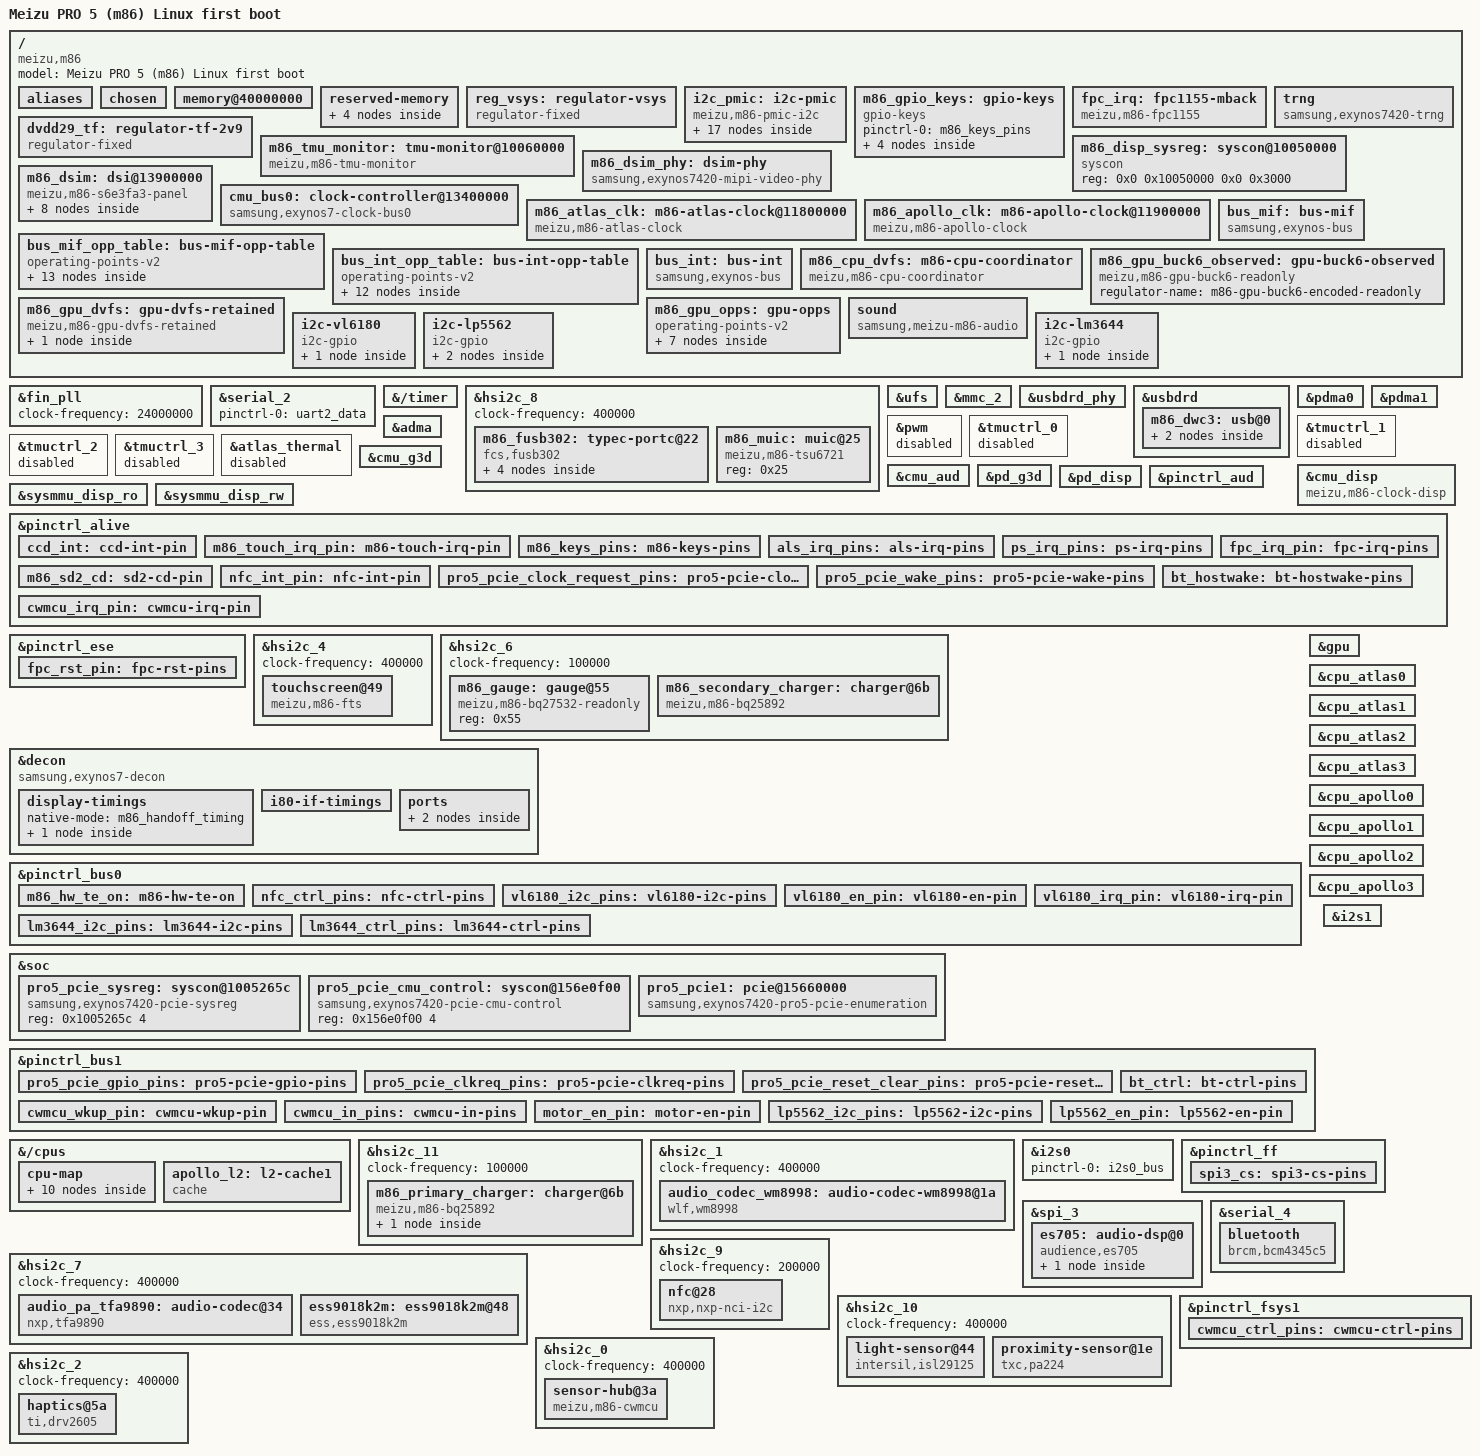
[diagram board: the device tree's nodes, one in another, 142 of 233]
// SPDX-License-Identifier: GPL-2.0-only
/*
 * Meizu PRO 5 (m86), conservative Linux 6.6 first-boot board description.
 * Board wiring: meizuosc/m576 ubuntu 5a0c442 and archived m86 raw DTB.
 * Requires the project's pinned Exynos7420 SoC patch (A53 + MCT nodes).
 */
/dts-v1/;

#include "exynos7.dtsi"
#include <dt-bindings/gpio/gpio.h>
#include <dt-bindings/input/ti-drv260x.h>
#include <dt-bindings/leds/common.h>
#include <dt-bindings/usb/pd.h>

/ {
	model = "Meizu PRO 5 (m86) Linux first boot";
	compatible = "meizu,m86", "samsung,exynos7420", "samsung,exynos7";

	aliases {
		serial0 = &serial_2;
		serial4 = &serial_4;
		i2c2 = &hsi2c_2;
		i2c6 = &hsi2c_6;
		i2c8 = &hsi2c_8;
		i2c10 = &hsi2c_10;
		i2c11 = &hsi2c_11;
		i2c5 = &i2c_pmic;
	};

	chosen {
		stdout-path = "serial0:115200n8";
		bootargs = "earlycon=exynos4210,0x14c30000 console=ttySAC0,115200n8 rdinit=/init maxcpus=8 clk_ignore_unused pd_ignore_unused loglevel=4 nokaslr no_console_suspend panic=5 oops=panic";
	};

	/*
	 * Built-in FDT: 3 GiB base map + placeholder for 4 GiB high bank
	 * [0x1_0000_0000, 0x1_4000_0000), populated at boot from firmware FDT.
	 */
	memory@40000000 {
		device_type = "memory";
		reg = <0x0 0x40000000 0x0 0xc0000000>,
		      <0x1 0x00000000 0x0 0x00000000>;
	};

	reserved-memory {
		#address-cells = <2>;
		#size-cells = <2>;
		ranges;

		/*
		 * Preserves only the bootloader display handoff buffer (through 0xe4800000).
		 * Reclaimed: vendor-log (32 MiB) and legacy modem/media/video (335.5 MiB).
		 */
		vendor-reserved@e1000000 {
			reg = <0x0 0xe1000000 0x0 0x03800000>;
			no-map;
		};

		/* Observed on 860BCMT226FG; matches the original Recovery SECLOG. */
		seclog@f9780000 {
			reg = <0x0 0xf9780000 0x0 0x00080000>;
			no-map;
		};

		vendor-reserved@f9800000 {
			reg = <0x0 0xf9800000 0x0 0x06800000>;
			no-map;
		};

		decon_iova_resv: decon-iova-reserved {
			iommu-addresses = <&decon 0xe0000000 0x04200000>;
		};
	};

	reg_vsys: regulator-vsys {
		compatible = "regulator-fixed";
		regulator-name = "vsys";
		regulator-min-microvolt = <3800000>;
		regulator-max-microvolt = <3800000>;
		regulator-always-on;
	};

	/*
	 * RTC-only PMIC path. The adapter checks/holds non-running APM in
	 * reset before requesting GPIOs. No default pinctrl state may run
	 * ahead of that guard. The regulator driver remains disabled.
	 */
	i2c_pmic: i2c-pmic {
		compatible = "meizu,m86-pmic-i2c", "i2c-gpio";
		meizu,pmu = <&pmu_system_controller>;
		#address-cells = <1>;
		#size-cells = <0>;
		sda-gpios = <&gpg3 2 (GPIO_ACTIVE_HIGH | GPIO_OPEN_DRAIN)>;
		scl-gpios = <&gpg3 3 (GPIO_ACTIVE_HIGH | GPIO_OPEN_DRAIN)>;
		i2c-gpio,delay-us = <5>;
		i2c-gpio,timeout-ms = <100>;
		status = "okay";

		pmic@66 {
			compatible = "samsung,s2mps15-pmic";
			reg = <0x66>;
			/* No PMIC IRQ: RTC read/write only, no alarm or wakeup. */
			regulators {
				/* Dynamic MIF, CPU, and INT rails: BUCK1, BUCK2, BUCK3, BUCK4 */
				m86_buck1_mif: BUCK1 {
					regulator-name = "vdd_mif";
					regulator-min-microvolt = <500000>;
					regulator-max-microvolt = <1100000>;
					regulator-always-on;
				};
				m86_buck2_cpu: BUCK2 {
					regulator-name = "vdd_atlas";
					regulator-min-microvolt = <500000>;
					regulator-max-microvolt = <1300000>;
					regulator-always-on;
					meizu,cpu-dvfs-active;
				};
				m86_buck3_cpu: BUCK3 {
					regulator-name = "vdd_apollo";
					regulator-min-microvolt = <500000>;
					regulator-max-microvolt = <1200000>;
					regulator-always-on;
					meizu,cpu-dvfs-active;
				};
				m86_buck4_int: BUCK4 {
					regulator-name = "vdd_int";
					regulator-min-microvolt = <500000>;
					regulator-max-microvolt = <1000000>;
					regulator-always-on;
				};
			};
		};
	};
};

&fin_pll {
	clock-frequency = <24000000>;
};

&serial_2 {
	pinctrl-names = "default";
	pinctrl-0 = <&uart2_data>;
	status = "okay";
};

/*
 * Preserve all MPIDRs, allowing the boot CPU to be identified whichever
 * cluster U-Boot entered. Bring up both clusters before capability finalization.
 * Stock PSCI 0.1 uses exactly the inherited CPU_ON/OFF function IDs.
 */
&{/timer} {
	clock-frequency = <24000000>;
	interrupt-names = "sec-phys", "phys", "hyp-phys";
	interrupts = <GIC_PPI 13 (GIC_CPU_MASK_SIMPLE(8) | IRQ_TYPE_LEVEL_LOW)>,
		     <GIC_PPI 14 (GIC_CPU_MASK_SIMPLE(8) | IRQ_TYPE_LEVEL_LOW)>,
		     <GIC_PPI 10 (GIC_CPU_MASK_SIMPLE(8) | IRQ_TYPE_LEVEL_LOW)>;
};

&hsi2c_8 {
	status = "okay";
	clock-frequency = <400000>;

	m86_fusb302: typec-portc@22 {
		compatible = "fcs,fusb302";
		reg = <0x22>;
		interrupt-parent = <&gpa1>;
		interrupts = <5 IRQ_TYPE_LEVEL_LOW>;
		pd-on-gpios = <&gpr3 4 GPIO_ACTIVE_HIGH>;
		pinctrl-names = "default";
		pinctrl-0 = <&ccd_int>;
		vbus-supply = <&usb_otg_vbus>;

		connector {
			compatible = "usb-c-connector";
			label = "USB-C";
			power-role = "dual";
			data-role = "dual";
			try-power-role = "sink";
			source-pdos = <PDO_FIXED(5000, 1500, PDO_FIXED_USB_COMM)>;
			sink-pdos = <
				PDO_FIXED(5000, 3000, PDO_FIXED_USB_COMM)
				PDO_FIXED(9000, 3000, PDO_FIXED_USB_COMM)
				PDO_FIXED(12000, 2000, PDO_FIXED_USB_COMM)
			>;
			op-sink-microwatt = <24000000>;
			usb-role-switch = <&m86_dwc3>;

			ports {
				#address-cells = <1>;
				#size-cells = <0>;

				port@0 {
					reg = <0>;
					usbc_hs: endpoint {
						remote-endpoint = <&dwc3_ep>;
					};
				};
			};
		};
	};
	m86_muic: muic@25 {
		compatible = "meizu,m86-tsu6721";
		reg = <0x25>;
	};
};

&ufs {
	samsung,bus = <&bus_mif>;
	interconnects = <&bus_int &bus_mif>;
	interconnect-names = "dma-mem";
	status = "okay";
};

&mmc_2 {
	status = "okay";
	num-slots = <1>;
	cap-sd-highspeed;
	sd-uhs-sdr12;
	sd-uhs-sdr25;
	sd-uhs-sdr50;
	sd-uhs-sdr104;
	sd-uhs-ddr50;
	card-detect-delay = <200>;
	samsung,dw-mshc-ciu-div = <3>;
	samsung,dw-mshc-sdr-timing = <3 0 3 2>;
	samsung,dw-mshc-ddr-timing = <3 0 2 1>;
	fifo-depth = <0x40>;
	bus-width = <4>;
	cd-gpios = <&gpa1 3 GPIO_ACTIVE_LOW>;
	vmmc-supply = <&dvdd29_tf>;
	vqmmc-supply = <&ldo2_reg>;
	pinctrl-names = "default";
	pinctrl-0 = <&sd2_clk &sd2_cmd &sd2_bus1 &sd2_bus4 &m86_sd2_cd>;
};

&usbdrd_phy {
	status = "okay";
};

&usbdrd {
	status = "okay";

	m86_dwc3: usb@0 {
		dr_mode = "otg";
		usb-role-switch;
		role-switch-default-mode = "peripheral";
		maximum-speed = "high-speed";
		snps,dis_u2_susphy_quirk;
		snps,dis_enblslpm_quirk;

		port {
			dwc3_ep: endpoint {
				remote-endpoint = <&usbc_hs>;
			};
		};
	};
};

/* Avoid unneeded first-boot accesses and the S6 display/audio sequences. */
&pdma0 { status = "okay"; };
&pdma1 { status = "okay"; };
&adma { status = "okay"; };
&pwm { status = "disabled"; };
&tmuctrl_0 { status = "disabled"; };
&tmuctrl_1 { status = "disabled"; };
&tmuctrl_2 { status = "disabled"; };
&tmuctrl_3 { status = "disabled"; };
&atlas_thermal { status = "disabled"; };
&cmu_g3d { status = "okay"; };
&cmu_aud { status = "okay"; };
&cmu_disp { status = "disabled"; };
&pd_g3d { status = "okay"; };
&pd_disp { status = "disabled"; };
&pinctrl_aud { status = "okay"; };
&sysmmu_disp_ro { status = "disabled"; };
&sysmmu_disp_rw { status = "disabled"; };

// SPDX-License-Identifier: GPL-2.0-only
/* Include after the board DTS root and pinctrl definitions.
 * PMIC supplies are retained from the bootloader, not registered/reconfigured.
 */
#include <dt-bindings/gpio/gpio.h>
#include <dt-bindings/input/input.h>
#include <dt-bindings/interrupt-controller/irq.h>

/ {
	m86_gpio_keys: gpio-keys {
		compatible = "gpio-keys";
		pinctrl-names = "default";
		pinctrl-0 = <&m86_keys_pins>;

		power {
			label = "Power";
			linux,code = <KEY_POWER>;
			gpios = <&gpa2 4 GPIO_ACTIVE_LOW>;
			debounce-interval = <25>;
			wakeup-source;
		};
		volume-down {
			label = "Volume down";
			linux,code = <KEY_VOLUMEDOWN>;
			gpios = <&gpa1 2 GPIO_ACTIVE_LOW>;
			debounce-interval = <10>;
		};
		volume-up {
			label = "Volume up";
			linux,code = <KEY_VOLUMEUP>;
			gpios = <&gpa0 7 GPIO_ACTIVE_LOW>;
			debounce-interval = <10>;
		};
		home {
			label = "Home";
			linux,code = <KEY_LEFTMETA>;
			gpios = <&gpa3 2 GPIO_ACTIVE_LOW>;
			debounce-interval = <10>;
			wakeup-source;
		};
	};

	fpc_irq: fpc1155-mback {
		compatible = "meizu,m86-fpc1155", "fpc,fpc_irq";
		irq-gpios = <&gpa2 2 GPIO_ACTIVE_HIGH>;
		reset-gpios = <&gpv7 4 GPIO_ACTIVE_HIGH>;
		vdd-supply = <&ldo14_reg>;
		clocks = <&clock_peric1 PCLK_SPI4>, <&clock_peric1 SCLK_SPI4>;
		clock-names = "pclk", "sclk";
		pinctrl-names = "default";
		pinctrl-0 = <&fpc_irq_pin &fpc_rst_pin>;
		wakeup-source;
	};

	dvdd29_tf: regulator-tf-2v9 {
		compatible = "regulator-fixed";
		regulator-name = "vmmc_sdcard";
		regulator-min-microvolt = <2900000>;
		regulator-max-microvolt = <2900000>;
		gpio = <&gpf2 2 GPIO_ACTIVE_HIGH>;
		enable-active-high;
	};

	trng {
		compatible = "samsung,exynos7420-trng", "samsung,exynos850-trng";
	};
};

&pinctrl_alive {
	ccd_int: ccd-int-pin {
		samsung,pins = "gpa1-5";
		samsung,pin-function = <0xf>;
		samsung,pin-pud = <0>;
	};
	m86_touch_irq_pin: m86-touch-irq-pin {
		samsung,pins = "gpa1-1";
		samsung,pin-function = <0xf>;
		samsung,pin-pud = <3>;
	};
	m86_keys_pins: m86-keys-pins {
		samsung,pins = "gpa2-4", "gpa1-2", "gpa0-7", "gpa3-2";
		samsung,pin-function = <0xf>;
		samsung,pin-pud = <0>;
	};
	als_irq_pins: als-irq-pins {
		samsung,pins = "gpa2-5";
		samsung,pin-function = <0xf>;
		samsung,pin-pud = <3>;
		samsung,pin-drv = <0>;
	};
	ps_irq_pins: ps-irq-pins {
		samsung,pins = "gpa3-4";
		samsung,pin-function = <0xf>;
		samsung,pin-pud = <3>;
		samsung,pin-drv = <0>;
	};
	fpc_irq_pin: fpc-irq-pins {
		samsung,pins = "gpa2-2";
		samsung,pin-function = <0xf>;
		samsung,pin-pud = <0>;
	};
	m86_sd2_cd: sd2-cd-pin {
		samsung,pins = "gpa1-3";
		samsung,pin-function = <0xf>;
		samsung,pin-pud = <3>;
	};
	nfc_int_pin: nfc-int-pin {
		samsung,pins = "gpa2-1";
		samsung,pin-function = <0xf>;
		samsung,pin-pud = <1>;
	};
};

&pinctrl_ese {
	fpc_rst_pin: fpc-rst-pins {
		samsung,pins = "gpv7-4";
		samsung,pin-function = <1>;
		samsung,pin-pud = <0>;
	};
};

&hsi2c_4 {
	status = "okay";
	clock-frequency = <400000>;
	touchscreen@49 {
		compatible = "meizu,m86-fts";
		reg = <0x49>;
		pinctrl-names = "default";
		pinctrl-0 = <&m86_touch_irq_pin>;
		interrupt-parent = <&gpa1>;
		interrupts = <1 IRQ_TYPE_LEVEL_LOW>;
		touchscreen-size-x = <1080>;
		touchscreen-size-y = <1920>;
	};
};

/* Integration proposal, not included by the active board DTS.
 * Keep the inherited Exynos7 TMU disabled; this monitor owns all four windows.
 * Driver enables clocks and sensing; no threshold or trim writes.
 * A 95 C software critical zone polls maximum of all four P0 sensors.
 */
/ {
	m86_tmu_monitor: tmu-monitor@10060000 {
		compatible = "meizu,m86-tmu-monitor";
		reg = <0 0x10060000 0 0x200>, <0 0x10064000 0 0x200>,
		      <0 0x10068000 0 0x200>, <0 0x1006c000 0 0x200>;
		interrupts = <GIC_SPI 108 IRQ_TYPE_LEVEL_HIGH>,
		             <GIC_SPI 124 IRQ_TYPE_LEVEL_HIGH>,
		             <GIC_SPI 109 IRQ_TYPE_LEVEL_HIGH>,
		             <GIC_SPI 107 IRQ_TYPE_LEVEL_HIGH>;
		clocks = <&clock_peris PCLK_TMU>, <&clock_peris SCLK_TMU>;
		clock-names = "tmu_apbif", "tmu_sclk";
	};
};

&hsi2c_6 {
	status = "okay";
	clock-frequency = <100000>;

	m86_gauge: gauge@55 {
		compatible = "meizu,m86-bq27532-readonly";
		reg = <0x55>;
	};
	m86_secondary_charger: charger@6b {
		compatible = "meizu,m86-bq25892", "ti,bq25892", "ti,bq25890";
		reg = <0x6b>;
		interrupt-parent = <&gpa0>;
		interrupts = <2 IRQ_TYPE_EDGE_FALLING>;
		enable-gpios = <&gpr3 2 GPIO_ACTIVE_LOW>;
		linux,skip-reset;
		ti,charge-current = <2250000>;
		ti,battery-regulation-voltage = <4352000>;
		ti,termination-current = <64000>;
		ti,precharge-current = <128000>;
		ti,minimum-sys-voltage = <3500000>;
		ti,boost-voltage = <5000000>;
		ti,boost-max-current = <500000>;
		ti,thermal-regulation-threshold = <80>;
		meizu,secondary-charger;
	};
};

&tmuctrl_0 { status = "disabled"; };
&tmuctrl_1 { status = "disabled"; };
&tmuctrl_2 { status = "disabled"; };
&tmuctrl_3 { status = "disabled"; };

/* Replace the empty regulators child on the board's existing S2MPS15 node.
 * These voltage constraints can write voltage at probe if firmware differs.
 * First read raw L18/19/21/23CTRL and record observed voltage/enable; don't
 * activate this proposal without evaluating the actual state.
 * Existing full constraints apply only to these registered rails on M86.
 */
&i2c_pmic {
  pmic@66 {
	regulators {
		m86_wm8998_1v8: LDO16 {
			regulator-name = "vdd18_audio";
			regulator-min-microvolt = <1800000>;
			regulator-max-microvolt = <1800000>;
			regulator-boot-on;
			regulator-always-on;
		};
		ldo17_reg: LDO17 {
			regulator-name = "vdd28_sen";
			regulator-min-microvolt = <2800000>;
			regulator-max-microvolt = <2800000>;
			regulator-boot-on;
			regulator-always-on;
		};
		m86_lcd_1v8: LDO18 {
			regulator-name = "vdd18_lcd";
			regulator-min-microvolt = <1800000>;
			regulator-max-microvolt = <1800000>;
			regulator-boot-on;
			regulator-always-on;
		};
		m86_lcd_3v3: LDO19 {
			regulator-name = "vdd33_lcd";
			regulator-min-microvolt = <3300000>;
			regulator-max-microvolt = <3300000>;
			regulator-boot-on;
			regulator-always-on;
		};
		m86_touch_3v3: LDO21 {
			regulator-name = "vdd33_touch";
			regulator-min-microvolt = <2900000>;
			regulator-max-microvolt = <2900000>;
			regulator-boot-on;
			regulator-always-on;
		};
		m86_es705_1v1: LDO22 {
			regulator-name = "vdd11_nr";
			regulator-min-microvolt = <1100000>;
			regulator-max-microvolt = <1100000>;
		};
		m86_touch_1v8: LDO23 {
			regulator-name = "vdd18_touch";
			regulator-min-microvolt = <1800000>;
			regulator-max-microvolt = <1800000>;
			regulator-boot-on;
			regulator-always-on;
		};
		ldo25_reg: LDO25 {
			regulator-name = "vdd28_ps";
			regulator-min-microvolt = <2800000>;
			regulator-max-microvolt = <2800000>;
			regulator-boot-on;
		};
		ldo14_reg: LDO14 {
			regulator-name = "vdd28_fp";
			regulator-min-microvolt = <1800000>;
			regulator-max-microvolt = <1800000>;
			regulator-boot-on;
			regulator-always-on;
		};
		ldo2_reg: LDO2 {
			regulator-name = "vqmmc_sdcard";
			regulator-min-microvolt = <1800000>;
			regulator-max-microvolt = <3300000>;
			regulator-boot-on;
		};
		ldo27_reg: LDO27 {
			regulator-name = "vdd18_nfc";
			regulator-min-microvolt = <1800000>;
			regulator-max-microvolt = <1800000>;
			regulator-boot-on;
			regulator-always-on;
		};
	};
  };
};

/* Command-mode display handoff from the bootloader. */
&cmu_disp { status = "okay"; };
&pd_disp { status = "okay"; };
&sysmmu_disp_ro { status = "okay"; };
&sysmmu_disp_rw { status = "okay"; };
&decon {
	compatible = "samsung,exynos7-decon";
	clocks = <&cmu_disp CLK_PCLK_DECON0>, <&cmu_disp CLK_ACLK_DECON0>,
	         <&cmu_disp CLK_SCLK_DECON0_ECLK>, <&cmu_disp CLK_SCLK_DECON0_VCLK>;
	clock-names = "pclk_decon0", "aclk_decon0", "decon0_eclk", "decon0_vclk";
	te-gpios = <&gpc0 1 GPIO_ACTIVE_HIGH>;
	samsung,bus = <&bus_mif>;
	interconnects = <&bus_int &bus_mif>;
	interconnect-names = "dma-mem";
	memory-region = <&decon_iova_resv>;
	status = "okay";
 display-timings {
  native-mode = <&m86_handoff_timing>;
  m86_handoff_timing: timing {
   clock-frequency = <125216000>;
   hactive = <1080>; vactive = <1920>;
   hfront-porch = <1>; hback-porch = <1>; hsync-len = <1>;
   vfront-porch = <5>; vback-porch = <1>; vsync-len = <1>;
  };
 };
 i80-if-timings { };
 ports {
  #address-cells = <1>;
  #size-cells = <0>;
  port@0 {
   reg = <0>;
   m86_decon_out: endpoint { remote-endpoint = <&m86_dsim_in>; };
  };
 };
};
// SPDX-License-Identifier: GPL-2.0-only
/* DSIM/PHY portion only. Parent adds DECON graph, panel/reset/TE and supplies. */
#include <dt-bindings/clock/exynos7-clk.h>
#include <dt-bindings/interrupt-controller/arm-gic.h>

/ {
	m86_disp_sysreg: syscon@10050000 {
		compatible = "syscon";
		reg = <0x0 0x10050000 0x0 0x3000>;
	};
	m86_dsim_phy: dsim-phy {
		compatible = "samsung,exynos7420-mipi-video-phy";
		samsung,pmu-syscon = <&pmu_system_controller>;
		samsung,disp-sysreg = <&m86_disp_sysreg>;
		#phy-cells = <1>;
	};
	m86_dsim: dsi@13900000 {
		/* Official HW TE input is separate from the gpc0-1 TE EINT. */
		pinctrl-names = "default";
		pinctrl-0 = <&m86_hw_te_on>;
		compatible = "samsung,exynos7420-mipi-dsi";
		reg = <0x0 0x13900000 0x0 0x1000>;
		interrupt-parent = <&gic>;
		interrupts = <GIC_SPI 196 IRQ_TYPE_LEVEL_HIGH>;
		clocks = <&cmu_disp CLK_PCLK_DSIM0>, <&fin_pll>,
			<&cmu_disp CLK_PHYCLK_MIPIDPHY0_BITCLKDIV8>,
			<&cmu_disp CLK_PHYCLK_MIPIDPHY0_RXCLKESC0>,
			<&cmu_disp CLK_SCLK_RGB_VCLK_TO_DSIM0>;
		clock-names = "bus_clk", "sclk_mipi",
			"phyclk_mipidphy0_bitclkdiv8",
			"phyclk_mipidphy0_rxclkesc0", "sclk_rgb_vclk_to_dsim0";
		assigned-clocks = <&cmu_disp CLK_MOUT_MIPIDPHY0_BIT>,
			<&cmu_disp CLK_MOUT_MIPIDPHY0_RX>;
		assigned-clock-parents = <&cmu_disp CLK_FOUT_MIPIDPHY0_BIT>,
			<&cmu_disp CLK_FOUT_MIPIDPHY0_RX>;
		phys = <&m86_dsim_phy 0>;
		phy-names = "dsim";
		samsung,pll-clock-frequency = <24000000>;
		samsung,burst-clock-frequency = <650000000>;
		samsung,esc-clock-frequency = <20000000>;
		samsung,mic-enabled;
		status = "disabled";
		/* Required: add vddcore/vddio supply phandles and ports/panel. */
	};
};
&m86_dsim {
 #address-cells = <1>;
 #size-cells = <0>;
 ports {
  #address-cells = <1>;
  #size-cells = <0>;
  port@0 {
   reg = <0>;
   m86_dsim_in: endpoint { remote-endpoint = <&m86_decon_out>; };
  };
  port@1 {
   reg = <1>;
   m86_dsim_out: endpoint { remote-endpoint = <&m86_panel_in>; data-lanes = <0 1>; };
  };
 };
 panel@0 {
  compatible = "meizu,m86-s6e3fa3";
  te-gpios = <&gpc0 1 GPIO_ACTIVE_HIGH>;
  reg = <0>;
  vci-supply = <&m86_lcd_3v3>;
  vdd3-supply = <&m86_lcd_1v8>;
  reset-gpios = <&gpc3 3 GPIO_ACTIVE_LOW>;
  port { m86_panel_in: endpoint { remote-endpoint = <&m86_dsim_out>; }; };
 };
};

/* Preserve the bootloader display clocks for the zenlte handoff path. */
&cmu_disp {
 /* Decode the inherited PLL correctly without retuning the live display. */
 compatible = "meizu,m86-clock-disp";
};

/ {
 cmu_bus0: clock-controller@13400000 {
  compatible = "samsung,exynos7-clock-bus0";
  reg = <0x0 0x13400000 0x0 0x1000>;
  #clock-cells = <1>;
  clocks = <&fin_pll>, <&clock_topc CLK_ACLK_BUS0_532>;
  clock-names = "fin_pll", "top_aclk_bus0_532";
 };
};

/* Handoff keeps the inherited TOP0 ECLK parent and divider. */


/* Official disp_teson: GPG0-1 function2 routes the external hardware TE. */
&pinctrl_bus0 {
 m86_hw_te_on: m86-hw-te-on {
  samsung,pins = "gpg0-1";
  samsung,pin-function = <2>;
 };
 nfc_ctrl_pins: nfc-ctrl-pins {
  samsung,pins = "gpc3-0", "gpc3-4", "gpc3-7";
  samsung,pin-function = <1>;
  samsung,pin-pud = <0>;
  samsung,pin-con-pdn = <3>;
 };
};

/* S6E3FA3 command-mode panel and backlight controller */
&m86_dsim {
	compatible = "meizu,m86-s6e3fa3-panel", "meizu,m86-dsim-handoff-backlight";
	/delete-property/ pinctrl-names;
	/delete-property/ pinctrl-0;
	/delete-property/ assigned-clocks;
	/delete-property/ assigned-clock-parents;
	default-brightness = <68>;
	status = "okay";
};

/* Experimental retained-power GPU bring-up only.
 * Require observed G3D domain/BUCK6 on before booting this candidate.
 * No regulator voltage/control claims: missing mali-supply uses dummy supply.
 * Preserve external domain power rather than introducing unverified m86 PM.
 */
&gpu {
	/delete-property/ power-domains;
	status = "okay";
};

/* CPU regulator consumer links only; no OPP or cpufreq enablement. */
&cpu_atlas0 { cpu-supply = <&m86_buck2_cpu>; };
&cpu_atlas1 { cpu-supply = <&m86_buck2_cpu>; };
&cpu_atlas2 { cpu-supply = <&m86_buck2_cpu>; };
&cpu_atlas3 { cpu-supply = <&m86_buck2_cpu>; };
&cpu_apollo0 { cpu-supply = <&m86_buck3_cpu>; };
&cpu_apollo1 { cpu-supply = <&m86_buck3_cpu>; };
&cpu_apollo2 { cpu-supply = <&m86_buck3_cpu>; };
&cpu_apollo3 { cpu-supply = <&m86_buck3_cpu>; };

/* SPDX-License-Identifier: GPL-2.0-only */
/* Include after exynos7420-m86.dts; candidate clock/header patch required. */
#include <dt-bindings/clock/exynos7-clk.h>
#include <dt-bindings/gpio/gpio.h>
#include <dt-bindings/interrupt-controller/arm-gic.h>

&soc {
	/* Preserve SoC MMIO and translate the channel-1 PCIe outbound aperture. */
	ranges = <0x00000000 0x0 0x00000000 0x18000000>,
	         <0x1c000000 0x0 0x1c000000 0x04000000>;
	/* Narrow SYSREG field, no existing syscon covers this register. */
	pro5_pcie_sysreg: syscon@1005265c {
		compatible = "samsung,exynos7420-pcie-sysreg", "syscon";
		reg = <0x1005265c 4>;
	};
	/* This word lies outside clock_fsys1's existing 0xd00 range. */
	pro5_pcie_cmu_control: syscon@156e0f00 {
		compatible = "samsung,exynos7420-pcie-cmu-control", "syscon";
		reg = <0x156e0f00 4>;
	};
	pro5_pcie1: pcie@15660000 {
		compatible = "samsung,exynos7420-pro5-pcie-enumeration";
		reg = <0x15660000 0x1000>, <0x15630000 0x1000>,
		      <0x156f00e4 4>, <0x157b0000 0x1000>,
		      <0x1c000000 0x1000>;
		reg-names = "elbi", "phy", "pcs", "dbi", "config";
		samsung,pcie-sysreg = <&pro5_pcie_sysreg>;
		samsung,pmu-syscon = <&pmu_system_controller>;
		samsung,pcie-cmu-control = <&pro5_pcie_cmu_control>;
		device_type = "pci";
		#address-cells = <3>;
		#size-cells = <2>;
		bus-range = <0 255>;
		/* Inbound identity DMA aperture for the installed 3GB DRAM. */
		dma-ranges = <0x02000000 0 0x40000000 0x40000000 0 0xc0000000>;
		ranges = <0x82000000 0 0x1c011000 0x1c011000 0 0x03feefff>;
		num-lanes = <1>;
		max-link-speed = <1>;
		interrupts = <GIC_SPI 205 IRQ_TYPE_LEVEL_HIGH>;
		interrupt-names = "elbi";
		/* Interrupts are masked by the enumeration-only driver. */
		reset-gpios = <&gpg2 0 GPIO_ACTIVE_LOW>;
		reg-on-gpios = <&gpf5 6 GPIO_ACTIVE_HIGH>;
		pinctrl-names = "default";
		pinctrl-0 = <&pro5_pcie_gpio_pins &pro5_pcie_clkreq_pins
		             &pro5_pcie_reset_clear_pins &pro5_pcie_wake_pins
		             &pro5_pcie_clock_request_pins>;
		clocks = <&clock_fsys1 ACLK_XIU_WIFI1X>,
		         <&clock_fsys1 ACLK_AHB2AXI_PCIE_WIFI1>,
		         <&clock_fsys1 ACLK_PCIE_WIFI1_MSTR>,
		         <&clock_fsys1 ACLK_PCIE_WIFI1_SLV>,
		         <&clock_fsys1 ACLK_PCIE_WIFI1_DBI>,
		         <&clock_fsys1 ACLK_COMBO_PHY_PCS_WIFI1>,
		         <&clock_fsys1 PCLK_ASYNC_COMBO_PHY_WIFI1>,
		         <&clock_fsys1 SCLK_PCIE_LINK_WIFI1>,
		         <&clock_fsys1 SCLK_COMBO_PHY_WIFI1_26M>,
		         <&clock_fsys1 SCLK_PHY_FSYS1_USER>,
		         <&clock_fsys1 PHYCLK_PCIE_WIFI1_TX0_USER>,
		         <&clock_fsys1 PHYCLK_PCIE_WIFI1_RX0_USER>,
		         <&clock_fsys1 MOUT_FSYS1_PHYCLK_SEL0>,
		         <&clock_fsys1 MOUT_PHYCLK_PCIE_WIFI1_TX0_USER>,
		         <&clock_fsys1 MOUT_PHYCLK_PCIE_WIFI1_RX0_USER>,
		         <&clock_fsys1 MOUT_SCLK_PHY_FSYS1_USER>,
		         <&fin_pll>, <&clock_fsys1 PHYCLK_PCIE_WIFI1_TX0>,
		         <&clock_fsys1 PHYCLK_PCIE_WIFI1_RX0>,
		         <&clock_top1 CLK_SCLK_PHY_FSYS1>;
		clock-names = "aclk_xiu_wifi1x", "aclk_ahb2axi_pcie_wifi1",
		              "aclk_pcie_wifi1_mstr_aclk", "aclk_pcie_wifi1_slv_aclk",
		              "aclk_pcie_wifi1_dbi_aclk", "aclk_combo_phy_pcs_pclk_wifi1",
		              "pclk_async_combo_phy_wifi1", "sclk_pcie_link_wifi1_gated",
		              "sclk_combo_phy_wifi1_26m_gated", "sclk_phy_fsys1_gated",
		              "phyclk_pcie_wifi1_tx0_gated", "phyclk_pcie_wifi1_rx0_gated",
		              "combo-ref-mux", "phy-tx-mux", "phy-rx-mux", "phy-user-mux",
		              "combo-ref-parent", "phy-tx-parent", "phy-rx-parent", "phy-user-parent";
		/* The module selects these four parents explicitly after stage0.
		 * No assigned-clock writes occur before manual driver logging.
		 */
		status = "okay";
	};
};

&pinctrl_bus1 {
	pro5_pcie_gpio_pins: pro5-pcie-gpio-pins {
		samsung,pins = "gpf5-6", "gpg2-0";
		samsung,pin-function = <1>;
		samsung,pin-drv = <3>;
	};
	pro5_pcie_clkreq_pins: pro5-pcie-clkreq-pins {
		samsung,pins = "gpf0-6";
		samsung,pin-function = <2>;
		samsung,pin-pud = <0>;
		samsung,pin-drv = <3>;
	};
	pro5_pcie_reset_clear_pins: pro5-pcie-reset-clear-pins {
		samsung,pins = "gpg2-2";
		samsung,pin-function = <2>;
		samsung,pin-pud = <3>;
	};
};

&pinctrl_alive {
	pro5_pcie_clock_request_pins: pro5-pcie-clock-request-pins {
		samsung,pins = "gpa3-5";
		samsung,pin-function = <0xf>;
		samsung,pin-pud = <0>;
	};
	pro5_pcie_wake_pins: pro5-pcie-wake-pins {
		samsung,pins = "gpa3-3";
		samsung,pin-function = <0>;
		samsung,pin-pud = <0>;
	};
};

/* Include only with m86-topc-cpu-safe-mux.patch and reviewed driver. */
/ {
	m86_atlas_clk: m86-atlas-clock@11800000 {
		compatible = "meizu,m86-atlas-clock";
		reg = <0 0x11800000 0 0x1000>;
		#clock-cells = <0>;
		clocks = <&clock_topc CLK_MOUT_BUS0_ATLAS>, <&fin_pll>;
		clock-names = "safe", "fin";
		meizu,max-validated-frequency = <2100000000>;
	};
	m86_apollo_clk: m86-apollo-clock@11900000 {
		compatible = "meizu,m86-apollo-clock";
		reg = <0 0x11900000 0 0x1000>;
		#clock-cells = <0>;
		clocks = <&clock_topc CLK_MOUT_BUS0_APOLLO>, <&fin_pll>;
		clock-names = "safe", "fin";
		meizu,max-validated-frequency = <1500000000>;
	};
};
&cpu_atlas0 { clocks = <&m86_atlas_clk>; };
&cpu_atlas1 { clocks = <&m86_atlas_clk>; };
&cpu_atlas2 { clocks = <&m86_atlas_clk>; };
&cpu_atlas3 { clocks = <&m86_atlas_clk>; };
&cpu_apollo0 { clocks = <&m86_apollo_clk>; };
&cpu_apollo1 { clocks = <&m86_apollo_clk>; };
&cpu_apollo2 { clocks = <&m86_apollo_clk>; };
&cpu_apollo3 { clocks = <&m86_apollo_clk>; };

/* Review proposal only. Calibration flags require source-backed unit evidence;
 * bus-floor property must NOT be added until actual fixed MIF/INT mapping verified.
 * Add label m86_tmu_monitor to existing sensor node separately before inclusion.
 */
/ {
	bus_mif_opp_table: bus-mif-opp-table {
		compatible = "operating-points-v2";

		opp-100000000 {
			opp-hz = /bits/ 64 <100000000>;
			opp-microvolt = <600000>;
			required-opps = <&int_opp_100>;
		};
		opp-133000000 {
			opp-hz = /bits/ 64 <133000000>;
			opp-microvolt = <600000>;
			required-opps = <&int_opp_200>;
		};
		opp-167000000 {
			opp-hz = /bits/ 64 <167000000>;
			opp-microvolt = <600000>;
			required-opps = <&int_opp_200>;
		};
		opp-276000000 {
			opp-hz = /bits/ 64 <276000000>;
			opp-microvolt = <600000>;
			required-opps = <&int_opp_200>;
		};
		opp-348000000 {
			opp-hz = /bits/ 64 <348000000>;
			opp-microvolt = <600000>;
			required-opps = <&int_opp_200>;
		};
		opp-416000000 {
			opp-hz = /bits/ 64 <416000000>;
			opp-microvolt = <600000>;
			required-opps = <&int_opp_200>;
		};
		opp-543000000 {
			opp-hz = /bits/ 64 <543000000>;
			opp-microvolt = <668750>;
			required-opps = <&int_opp_200>;
		};
		opp-632000000 {
			opp-hz = /bits/ 64 <632000000>;
			opp-microvolt = <681250>;
			required-opps = <&int_opp_266>;
		};
		opp-828000000 {
			opp-hz = /bits/ 64 <828000000>;
			opp-microvolt = <725000>;
			required-opps = <&int_opp_334>;
		};
		opp-1026000000 {
			opp-hz = /bits/ 64 <1026000000>;
			opp-microvolt = <743750>;
			required-opps = <&int_opp_500>;
		};
		opp-1264000000 {
			opp-hz = /bits/ 64 <1264000000>;
			opp-microvolt = <768750>;
			required-opps = <&int_opp_520>;
		};
		opp-1456000000 {
			opp-hz = /bits/ 64 <1456000000>;
			opp-microvolt = <800000>;
			required-opps = <&int_opp_540>;
		};
		opp-1552000000 {
			opp-hz = /bits/ 64 <1552000000>;
			opp-microvolt = <837500>;
			required-opps = <&int_opp_560>;
		};
	};

	bus_int_opp_table: bus-int-opp-table {
		compatible = "operating-points-v2";

		int_opp_100: opp-100000000 {
			opp-hz = /bits/ 64 <100000000>;
			opp-microvolt = <700000>;
		};
		int_opp_200: opp-200000000 {
			opp-hz = /bits/ 64 <200000000>;
			opp-microvolt = <700000>;
		};
		int_opp_266: opp-266000000 {
			opp-hz = /bits/ 64 <266000000>;
			opp-microvolt = <700000>;
		};
		int_opp_334: opp-334000000 {
			opp-hz = /bits/ 64 <334000000>;
			opp-microvolt = <700000>;
		};
		int_opp_400: opp-400000000 {
			opp-hz = /bits/ 64 <400000000>;
			opp-microvolt = <725000>;
		};
		int_opp_500: opp-500000000 {
			opp-hz = /bits/ 64 <500000000>;
			opp-microvolt = <750000>;
		};
		int_opp_510: opp-510000000 {
			opp-hz = /bits/ 64 <510000000>;
			opp-microvolt = <750000>;
		};
		int_opp_520: opp-520000000 {
			opp-hz = /bits/ 64 <520000000>;
			opp-microvolt = <750000>;
		};
		int_opp_530: opp-530000000 {
			opp-hz = /bits/ 64 <530000000>;
			opp-microvolt = <750000>;
		};
		int_opp_540: opp-540000000 {
			opp-hz = /bits/ 64 <540000000>;
			opp-microvolt = <750000>;
		};
		int_opp_550: opp-550000000 {
			opp-hz = /bits/ 64 <550000000>;
			opp-microvolt = <806250>;
		};
		int_opp_560: opp-560000000 {
			opp-hz = /bits/ 64 <560000000>;
			opp-microvolt = <806250>;
		};
	};

	bus_mif: bus-mif {
		compatible = "samsung,exynos-bus";
		operating-points-v2 = <&bus_mif_opp_table>;
		#interconnect-cells = <0>;
		vdd-supply = <&m86_buck1_mif>;
		status = "okay";
	};

	bus_int: bus-int {
		compatible = "samsung,exynos-bus";
		operating-points-v2 = <&bus_int_opp_table>;
		#interconnect-cells = <0>;
		interconnects = <&bus_mif>;
		vdd-supply = <&m86_buck4_int>;
		devfreq = <&bus_mif>;
		status = "okay";
	};

	m86_cpu_dvfs: m86-cpu-coordinator {
		compatible = "meizu,m86-cpu-coordinator";
		meizu,ema-syscon = <&m86_disp_sysreg>;
		clocks = <&m86_atlas_clk>, <&m86_apollo_clk>, <&fin_pll>;
		clock-names = "atlas", "apollo", "fin";
		atlas-supply = <&m86_buck2_cpu>;
		apollo-supply = <&m86_buck3_cpu>;
		meizu,thermal-monitor = <&m86_tmu_monitor>;
		meizu,max-validated-khz = <2100000 1500000>;
		/* Intentionally no meizu,cpu-dvfs-active or validated-bus-floor gate. */
		status = "disabled";
	};
};

/* Explicit firstboot proposal only: include after clock and coordinator nodes.
 * Uses accepted unit-specific ASV/EMA fuse/MIF evidence. Boot EMA register
 * readbacks must also match; driver refuses otherwise. No automatic governor.
 */
&m86_cpu_dvfs {
	status = "okay";
	meizu,cpu-dvfs-active;
	samsung,bus = <&bus_mif>;
	meizu,max-validated-khz = <2100000 1500000>;
};

// SPDX-License-Identifier: GPL-2.0-only
/ {
 m86_gpu_buck6_observed: gpu-buck6-observed {
  compatible = "meizu,m86-gpu-buck6-readonly";
  regulator-name = "m86-gpu-buck6-encoded-readonly";
 };
};
&gpu { mali-supply = <&m86_gpu_buck6_observed>; };

// SPDX-License-Identifier: GPL-2.0-only
/* Requires prior retained-power GPU, guarded PMIC access and readonlyrail.
 * Normal ON fixed-LDO candidate: explicit266/350MHz selector protocol.
 */
/ {
 m86_gpu_dvfs: gpu-dvfs-retained {
  compatible = "meizu,m86-gpu-dvfs-retained";
  #clock-cells = <0>;
  clocks = <&fin_pll>, <&m86_apollo_clk>;
  clock-names = "fin", "apollo";
  samsung,bus = <&bus_mif>;
  meizu,gpu = <&gpu>;
  meizu,sysreg = <&m86_disp_sysreg>;
  meizu,retained-g3d-ownership;
  meizu,max-validated-frequency = <700000000>;
  meizu,validated-buck6-normal-on;
  meizu,gpu-normal-on-takeover;
  /* Retained external G3D domain (0x4100=0xf) + Panfrost 50ms internal
   * shader/tiler/L2 power-off and devfreq suspend (validated in r62d/r62e/r71/r72). */
  meizu,thermal-monitor = <&m86_tmu_monitor>;
  m86_g3d_experiment: g3d-domain {
   #power-domain-cells = <0>;
  };
 };
 m86_gpu_opps: gpu-opps {
  compatible = "operating-points-v2";
  /* Frequency-only governor/cooling table: coordinator owns voltage/MCS.
   * Full hardware table remains in C source. Enable next OPPs only together
   * with validation flag+clockcap; governor must not request unvalidatedrates.
   */
  opp-266000000 { opp-hz = /bits/ 64 <266000000>; };
  opp-350000000 { opp-hz = /bits/ 64 <350000000>; };
  opp-420000000 { opp-hz = /bits/ 64 <420000000>; };
  opp-544000000 { opp-hz = /bits/ 64 <544000000>; };
  opp-600000000 { opp-hz = /bits/ 64 <600000000>; };
  opp-700000000 { opp-hz = /bits/ 64 <700000000>; };
  /* Retained for a separately validated 772 MHz experiment. */
  opp-772000000 { opp-hz = /bits/ 64 <772000000>; status = "disabled"; };
 };
};
&gpu {
 clocks = <&m86_gpu_dvfs>, <&cmu_g3d CLK_PCLK_SYSREG_G3D>;
 clock-names = "core", "bus";
 mali-supply = <&m86_gpu_buck6_observed>;
 operating-points-v2 = <&m86_gpu_opps>;
 meizu,gpu-dvfs-coordinator = <&m86_gpu_dvfs>;
};

/* Relative per-MHz capacities derived from the Android nominal max-capacity
 * ratio 419/1024 at 1.5/2.1 GHz. arch_topology multiplies by each policy max
 * frequency: 2933*1500*1024/(5120*2100)=419, not 419*1500/(1024*2100).
 * Nominal compatibility values, not new DMIPS benchmark measurements.
 */
&cpu_atlas0 { capacity-dmips-mhz = <5120>; };
&cpu_atlas1 { capacity-dmips-mhz = <5120>; };
&cpu_atlas2 { capacity-dmips-mhz = <5120>; };
&cpu_atlas3 { capacity-dmips-mhz = <5120>; };
&cpu_apollo0 { capacity-dmips-mhz = <2933>; };
&cpu_apollo1 { capacity-dmips-mhz = <2933>; };
&cpu_apollo2 { capacity-dmips-mhz = <2933>; };
&cpu_apollo3 { capacity-dmips-mhz = <2933>; };

/* Native capacity parsing requires complete cpu-map. */
&{/cpus} {
 cpu-map {
  cluster0 {
   core0 { cpu = <&cpu_apollo0>; };
   core1 { cpu = <&cpu_apollo1>; };
   core2 { cpu = <&cpu_apollo2>; };
   core3 { cpu = <&cpu_apollo3>; };
  };
  cluster1 {
   core0 { cpu = <&cpu_atlas0>; };
   core1 { cpu = <&cpu_atlas1>; };
   core2 { cpu = <&cpu_atlas2>; };
   core3 { cpu = <&cpu_atlas3>; };
  };
 };
 apollo_l2: l2-cache1 { compatible = "cache"; cache-level = <2>; cache-unified; };
};
&cpu_apollo0 { next-level-cache = <&apollo_l2>; };
&cpu_apollo1 { next-level-cache = <&apollo_l2>; };
&cpu_apollo2 { next-level-cache = <&apollo_l2>; };
&cpu_apollo3 { next-level-cache = <&apollo_l2>; };

&hsi2c_11 {
	status = "okay";
	clock-frequency = <100000>;

	m86_primary_charger: charger@6b {
		compatible = "meizu,m86-bq25892", "ti,bq25892", "ti,bq25890";
		reg = <0x6b>;
		interrupt-parent = <&gpa0>;
		interrupts = <3 IRQ_TYPE_EDGE_FALLING>;
		enable-gpios = <&gpr3 0 GPIO_ACTIVE_LOW>;
		linux,skip-reset;
		ti,charge-current = <2250000>;
		ti,battery-regulation-voltage = <4352000>;
		ti,termination-current = <64000>;
		ti,precharge-current = <128000>;
		ti,minimum-sys-voltage = <3500000>;
		ti,boost-voltage = <5000000>;
		ti,boost-max-current = <1500000>;
		ti,thermal-regulation-threshold = <80>;
		meizu,battery = <&m86_gauge>;
		meizu,usb-source = <&m86_fusb302>;
		linux,secondary-charger-name = "m86-charger-aux";

		usb_otg_vbus: usb-otg-vbus {
			regulator-name = "usb_otg_vbus";
		};
	};
};

&hsi2c_1 {
	status = "okay";
	clock-frequency = <400000>;

	audio_codec_wm8998: audio-codec-wm8998@1a {
		compatible = "wlf,wm8998";
		reg = <0x1a>;
		interrupt-parent = <&gpa3>;
		interrupts = <6 IRQ_TYPE_LEVEL_HIGH>;

		wlf,reset = <&gpd0 1 GPIO_ACTIVE_HIGH>;
		reset-gpios = <&gpd0 1 GPIO_ACTIVE_HIGH>;
		wlf,ldoena = <&gpj0 2 GPIO_ACTIVE_HIGH>;

		wlf,micd-ranges = <
			105 226 /* KEY_MEDIA */
			270 115 /* KEY_VOLUMEUP */
			752 114 /* KEY_VOLUMEDOWN */ >;
		wlf,micd-configs = <0 1 0>;
		wlf,micbias1 = <2600 0 1 0 0>;
		wlf,micbias2 = <1800 0 1 0 0>;
		wlf,micbias3 = <1800 0 1 0 0>;
		wlf,clk32k-src = <2>; /* MCLK2 */
		wlf,micd-detect-debounce = <500>;
		wlf,micd-bias-start-time = <9>;
		wlf,micd-rate = <5>;
		wlf,micd-dbtime = <1>;
		wlf,micd-force-micbias = <1>;
		wlf,micd-open-circuit-declare = <1>;

		#sound-dai-cells = <1>;

		AVDD-supply = <&m86_wm8998_1v8>;
		LDOVDD-supply = <&m86_wm8998_1v8>;
		DBVDD-supply = <&m86_wm8998_1v8>;
		DBVDD1-supply = <&m86_wm8998_1v8>;
		DBVDD2-supply = <&m86_wm8998_1v8>;
		DBVDD3-supply = <&m86_wm8998_1v8>;
		CPVDD-supply = <&m86_wm8998_1v8>;
		SPKVDD-supply = <&m86_wm8998_1v8>;
		SPKVDDL-supply = <&m86_wm8998_1v8>;
		SPKVDDR-supply = <&m86_wm8998_1v8>;
	};
};

&i2s0 {
	status = "okay";
	pinctrl-names = "default";
	pinctrl-0 = <&i2s0_bus>;
};

&i2s1 {
	status = "okay";
};

&pinctrl_ff {
	spi3_cs: spi3-cs-pins {
		samsung,pins = "gpg4-1";
		samsung,pin-function = <EXYNOS_PIN_FUNC_OUTPUT>;
		samsung,pin-pud = <EXYNOS_PIN_PULL_UP>;
		samsung,pin-drv = <EXYNOS7_PIN_DRV_LV1>;
	};
};

&spi_3 {
	status = "okay";
	pinctrl-names = "default";
	pinctrl-0 = <&spi3_bus &spi3_cs>;
	cs-gpios = <&gpg4 1 GPIO_ACTIVE_LOW>;
	num-cs = <1>;

	es705: audio-dsp@0 {
		compatible = "audience,es705";
		reg = <0>;
		spi-max-frequency = <4000000>;
		spi-cpha;
		controller-data {
			samsung,spi-feedback-delay = <0>;
		};
	};
};

&hsi2c_7 {
	status = "okay";
	clock-frequency = <400000>;

	audio_pa_tfa9890: audio-codec@34 {
		compatible = "nxp,tfa9890";
		reg = <0x34>;
		vddd-supply = <&m86_wm8998_1v8>;
		reset-gpios = <&gpf3 1 GPIO_ACTIVE_HIGH>;
		#sound-dai-cells = <0>;
	};

	ess9018k2m: ess9018k2m@48 {
		compatible = "ess,ess9018k2m";
		reg = <0x48>;
		osc48k-gpios = <&gpf2 1 GPIO_ACTIVE_HIGH>;
		osc44k-gpios = <&gpf2 3 GPIO_ACTIVE_HIGH>;
		reset-gpios = <&gpf0 4 GPIO_ACTIVE_HIGH>;
		mute-gpios = <&gpf1 3 GPIO_ACTIVE_HIGH>;
		open-gpios = <&gpf5 0 GPIO_ACTIVE_HIGH>;
		low-gain-gpios = <&gpf1 0 GPIO_ACTIVE_HIGH>;
		out-select-gpios = <&gpf1 4 GPIO_ACTIVE_HIGH>;
		dvdd18-gpios = <&gpf4 1 GPIO_ACTIVE_HIGH>;
		#sound-dai-cells = <0>;
	};
};

/ {
	sound {
		compatible = "samsung,meizu-m86-audio";
		model = "Meizu-PRO5";
		samsung,pmu = <&pmu_system_controller>;
		samsung,rtc = <&rtc>;
		samsung,dsp = <&es705>;
		dsp-reset-gpios = <&gpf5 5 GPIO_ACTIVE_HIGH>;
		dsp-wakeup-gpios = <&gpd5 1 GPIO_ACTIVE_HIGH>;
		dsp-core-supply = <&m86_es705_1v1>;
		audio-amplifier = <&audio_pa_tfa9890>;
		hifi-cpu = <&i2s0 0>;
		hifi-dac = <&ess9018k2m>;
		samsung,audio-routing =
			"Headphone", "HPOUTL",
			"Headphone", "HPOUTR",
			"Earpiece", "EPOUT",
			"AIFINL", "AIF3TX1",
			"AIFINR", "AIF3TX2",
			"Speaker", "OUT",
			"Headset Mic", "MICBIAS1",
			"IN2B", "Headset Mic",
			"Main Mic", "MICBIAS2",
			"IN1AL", "Main Mic";
		audio-codec = <&audio_codec_wm8998 1>;
		i2s-controller = <&i2s1 0>;
		status = "okay";
	};
};

&pinctrl_alive {
	bt_hostwake: bt-hostwake-pins {
		samsung,pins = "gpa2-6";
		samsung,pin-function = <EXYNOS_PIN_FUNC_EINT>;
		samsung,pin-pud = <EXYNOS_PIN_PULL_DOWN>;
		samsung,pin-drv = <EXYNOS7_PIN_DRV_LV1>;
	};
};

&pinctrl_bus1 {
	bt_ctrl: bt-ctrl-pins {
		samsung,pins = "gpf5-7", "gpf4-0";
		samsung,pin-function = <EXYNOS_PIN_FUNC_OUTPUT>;
		samsung,pin-pud = <EXYNOS_PIN_PULL_NONE>;
		samsung,pin-drv = <EXYNOS7_PIN_DRV_LV1>;
	};
};

&serial_4 {
	status = "okay";
	pinctrl-names = "default";
	pinctrl-0 = <&uart4_bus &bt_ctrl &bt_hostwake>;
	samsung,uart-fifosize = <64>;

	bluetooth {
		compatible = "brcm,bcm4345c5";
		max-speed = <1500000>;
		shutdown-gpios = <&gpf5 7 GPIO_ACTIVE_HIGH>;
		device-wakeup-gpios = <&gpf4 0 GPIO_ACTIVE_HIGH>;
		interrupt-parent = <&gpa2>;
		interrupts = <6 IRQ_TYPE_EDGE_RISING>;
		interrupt-names = "host-wakeup";
	};
};

&hsi2c_9 {
	status = "okay";
	clock-frequency = <200000>;

	nfc@28 {
		compatible = "nxp,nxp-nci-i2c";
		reg = <0x28>;
		interrupt-parent = <&gpa2>;
		interrupts = <1 IRQ_TYPE_LEVEL_HIGH>;
		enable-gpios = <&gpc3 0 GPIO_ACTIVE_HIGH>;
		firmware-gpios = <&gpc3 4 GPIO_ACTIVE_HIGH>;
		pinctrl-names = "default";
		pinctrl-0 = <&nfc_int_pin &nfc_ctrl_pins>;
	};
};

&hsi2c_10 {
	status = "okay";
	clock-frequency = <400000>;

	light-sensor@44 {
		compatible = "intersil,isl29125";
		reg = <0x44>;
		interrupt-parent = <&gpa2>;
		interrupts = <5 IRQ_TYPE_EDGE_FALLING>;
		pinctrl-names = "default";
		pinctrl-0 = <&als_irq_pins>;
		vdd-supply = <&ldo17_reg>;
		meizu,lux-coef = <16399>;
	};

	proximity-sensor@1e {
		compatible = "txc,pa224";
		reg = <0x1e>;
		interrupt-parent = <&gpa3>;
		interrupts = <4 IRQ_TYPE_EDGE_FALLING>;
		pinctrl-names = "default";
		pinctrl-0 = <&ps_irq_pins>;
		vdd-supply = <&ldo17_reg>;
		vdd-led-supply = <&ldo25_reg>;
	};
};

&pinctrl_bus0 {
	vl6180_i2c_pins: vl6180-i2c-pins {
		samsung,pins = "gpc2-2", "gpc2-3";
		samsung,pin-function = <0>;
		samsung,pin-pud = <3>;
		samsung,pin-drv = <0>;
	};

	vl6180_en_pin: vl6180-en-pin {
		samsung,pins = "gpd7-2";
		samsung,pin-function = <1>;
		samsung,pin-pud = <0>;
		samsung,pin-drv = <0>;
	};

	vl6180_irq_pin: vl6180-irq-pin {
		samsung,pins = "gpc3-6";
		samsung,pin-function = <0>;
		samsung,pin-pud = <3>;
		samsung,pin-drv = <0>;
	};

	lm3644_i2c_pins: lm3644-i2c-pins {
		samsung,pins = "gpc2-4", "gpc2-5";
		samsung,pin-function = <0>;
		samsung,pin-pud = <3>;
		samsung,pin-drv = <0>;
	};

	lm3644_ctrl_pins: lm3644-ctrl-pins {
		samsung,pins = "gpc0-0", "gpc0-3", "gpc0-4";
		samsung,pin-function = <0>;
		samsung,pin-pud = <0>;
		samsung,pin-drv = <0>;
	};
};

/ {
	i2c-vl6180 {
		compatible = "i2c-gpio";
		sda-gpios = <&gpc2 2 (GPIO_ACTIVE_HIGH | GPIO_OPEN_DRAIN)>;
		scl-gpios = <&gpc2 3 (GPIO_ACTIVE_HIGH | GPIO_OPEN_DRAIN)>;
		i2c-gpio,delay-us = <2>;
		pinctrl-names = "default";
		pinctrl-0 = <&vl6180_i2c_pins>;
		#address-cells = <1>;
		#size-cells = <0>;

		tof@29 {
			compatible = "st,vl6180";
			reg = <0x29>;
			vdd-supply = <&ldo25_reg>;
			enable-gpios = <&gpd7 2 GPIO_ACTIVE_HIGH>;
			interrupt-parent = <&gpc3>;
			interrupts = <6 IRQ_TYPE_EDGE_FALLING>;
			pinctrl-names = "default";
			pinctrl-0 = <&vl6180_en_pin &vl6180_irq_pin>;
			st,disable-als;
		};
	};

	i2c-lp5562 {
		compatible = "i2c-gpio";
		sda-gpios = <&gpf1 6 (GPIO_ACTIVE_HIGH | GPIO_OPEN_DRAIN)>;
		scl-gpios = <&gpf1 7 (GPIO_ACTIVE_HIGH | GPIO_OPEN_DRAIN)>;
		i2c-gpio,delay-us = <2>;
		pinctrl-names = "default";
		pinctrl-0 = <&lp5562_i2c_pins>;
		#address-cells = <1>;
		#size-cells = <0>;

		led-controller@30 {
			compatible = "ti,lp5562";
			reg = <0x30>;
			clock-mode = /bits/ 8 <1>;
			enable-gpios = <&gpf5 4 GPIO_ACTIVE_HIGH>;
			pinctrl-names = "default";
			pinctrl-0 = <&lp5562_en_pin>;
			#address-cells = <1>;
			#size-cells = <0>;

			led@0 {
				reg = <0>;
				chan-name = "m86:white:breath";
				color = <LED_COLOR_ID_WHITE>;
				led-cur = /bits/ 8 <80>;
				max-cur = /bits/ 8 <80>;
				linux,default-trigger = "heartbeat";
			};
		};
	};

	i2c-lm3644 {
		compatible = "i2c-gpio";
		sda-gpios = <&gpc2 4 (GPIO_ACTIVE_HIGH | GPIO_OPEN_DRAIN)>;
		scl-gpios = <&gpc2 5 (GPIO_ACTIVE_HIGH | GPIO_OPEN_DRAIN)>;
		i2c-gpio,delay-us = <2>;
		pinctrl-names = "default";
		pinctrl-0 = <&lm3644_i2c_pins>;
		#address-cells = <1>;
		#size-cells = <0>;

		flash-led-controller@63 {
			compatible = "ti,leds-lm3644", "ti,lm3644";
			reg = <0x63>;
			hwen-gpios = <&gpc0 4 GPIO_ACTIVE_HIGH>;
			strobe-gpios = <&gpc0 0 GPIO_ACTIVE_HIGH>;
			pinctrl-names = "default";
			pinctrl-0 = <&lm3644_ctrl_pins>;
		};
	};
};

&pinctrl_alive {
	cwmcu_irq_pin: cwmcu-irq-pin {
		samsung,pins = "gpa1-7";
		samsung,pin-function = <0xf>;
		samsung,pin-pud = <3>;
		samsung,pin-drv = <0>;
	};
};

&pinctrl_bus1 {
	cwmcu_wkup_pin: cwmcu-wkup-pin {
		samsung,pins = "gpf3-3";
		samsung,pin-function = <1>;
		samsung,pin-pud = <1>;
		samsung,pin-drv = <0>;
	};

	cwmcu_in_pins: cwmcu-in-pins {
		samsung,pins = "gpf0-2", "gpf4-5";
		samsung,pin-function = <0>;
		samsung,pin-pud = <1>;
		samsung,pin-drv = <0>;
	};

	motor_en_pin: motor-en-pin {
		samsung,pins = "gpf1-1";
		samsung,pin-function = <1>;
		samsung,pin-pud = <0>;
		samsung,pin-drv = <0>;
	};

	lp5562_i2c_pins: lp5562-i2c-pins {
		samsung,pins = "gpf1-6", "gpf1-7";
		samsung,pin-function = <0>;
		samsung,pin-pud = <3>;
		samsung,pin-drv = <0>;
	};

	lp5562_en_pin: lp5562-en-pin {
		samsung,pins = "gpf5-4";
		samsung,pin-function = <1>;
		samsung,pin-pud = <0>;
		samsung,pin-drv = <0>;
	};
};

&pinctrl_fsys1 {
	cwmcu_ctrl_pins: cwmcu-ctrl-pins {
		samsung,pins = "gpr0-0", "gpr0-2";
		samsung,pin-function = <1>;
		samsung,pin-pud = <1>;
		samsung,pin-drv = <0>;
	};
};

&hsi2c_0 {
	status = "okay";
	clock-frequency = <400000>;

	sensor-hub@3a {
		compatible = "meizu,m86-cwmcu", "st,sensor_hub";
		reg = <0x3a>;
		vdd-supply = <&ldo17_reg>;
		interrupt-parent = <&gpa1>;
		interrupts = <7 IRQ_TYPE_EDGE_FALLING>;
		wakeup-gpios = <&gpf3 3 GPIO_ACTIVE_HIGH>;
		sleep-gpios = <&gpf0 2 GPIO_ACTIVE_HIGH>;
		busy-gpios = <&gpf4 5 GPIO_ACTIVE_HIGH>;
		reset-gpios = <&gpr0 0 GPIO_ACTIVE_HIGH>;
		boot0-gpios = <&gpr0 2 GPIO_ACTIVE_HIGH>;
		mount-matrix = "-1", "0", "0",
			       "0", "-1", "0",
			       "0", "0", "1";
		pinctrl-names = "default";
		pinctrl-0 = <&cwmcu_irq_pin &cwmcu_wkup_pin &cwmcu_in_pins &cwmcu_ctrl_pins>;
		wakeup-source;
	};
};

&hsi2c_2 {
	status = "okay";
	clock-frequency = <400000>;

	haptics@5a {
		compatible = "ti,drv2605";
		reg = <0x5a>;
		vbat-supply = <&reg_vsys>;
		enable-gpios = <&gpf1 1 GPIO_ACTIVE_HIGH>;
		mode = <DRV260X_LRA_NO_CAL_MODE>;
		library-sel = <DRV260X_LIB_LRA>;
		vib-rated-mv = <1757>;
		vib-overdrive-mv = <2900>;
		pinctrl-names = "default";
		pinctrl-0 = <&motor_en_pin>;
	};
};
